# STM32F0x0 register map
File version: 1.2
CPU: CM0 r0p0, little endian, no MPU, no FPU, 3 interrupt priority bits
Registers are 32-bit, read-write, reset 0x0 unless marked. A register's access mark holds for its fields unless they carry their own. Offsets are from the block's base; [hi:lo] are bit positions.

## Flash
Base 0x40022000
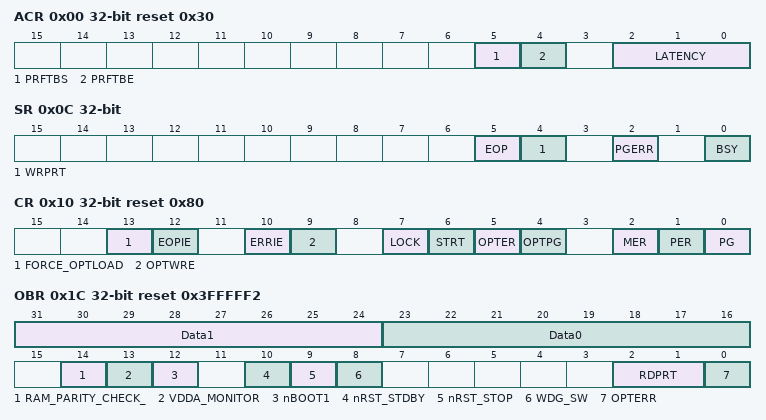
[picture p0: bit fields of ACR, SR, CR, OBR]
0x00 ACR access per field reset 0x30 — Flash access control register
  [5] PRFTBS ro, [4] PRFTBE rw, [2:0] LATENCY rw
0x04 KEYR wo — Flash key register
  [31:0] FKEYR — Flash Key
0x08 OPTKEYR wo — Flash option key register
  [31:0] OPTKEYR — Option byte key
0x0C SR access per field — Flash status register
  [5] EOP rw — End of operation
  [4] WRPRT rw — Write protection error
  [2] PGERR rw — Programming error
  [0] BSY ro — Busy
0x10 CR reset 0x80 — Flash control register
  [13] FORCE_OPTLOAD — Force option byte loading
  [12] EOPIE — End of operation interrupt enable
  [10] ERRIE — Error interrupt enable
  [9] OPTWRE — Option bytes write enable
  [7] LOCK
  [6] STRT — Start
  [5] OPTER — Option byte erase
  [4] OPTPG — Option byte programming
  [2] MER — Mass erase
  [1] PER — Page erase
  [0] PG — Programming
0x14 AR wo — Flash address register
  [31:0] FAR — Flash address
0x1C OBR ro reset 0x3FFFFF2 — Option byte register
  [31:24] Data1
  [23:16] Data0
  [14] RAM_PARITY_CHECK_
  [13] VDDA_MONITOR
  [12] nBOOT1 — BOOT1
  [10] nRST_STDBY
  [9] nRST_STOP
  [8] WDG_SW
  [2:1] RDPRT — Read protection level status
  [0] OPTERR — Option byte error
0x20 WRPR ro reset 0xFFFFFFFF — Write protection register
  [31:0] WRP — Write protect

## DBGMCU — Debug support
Base 0x40015800
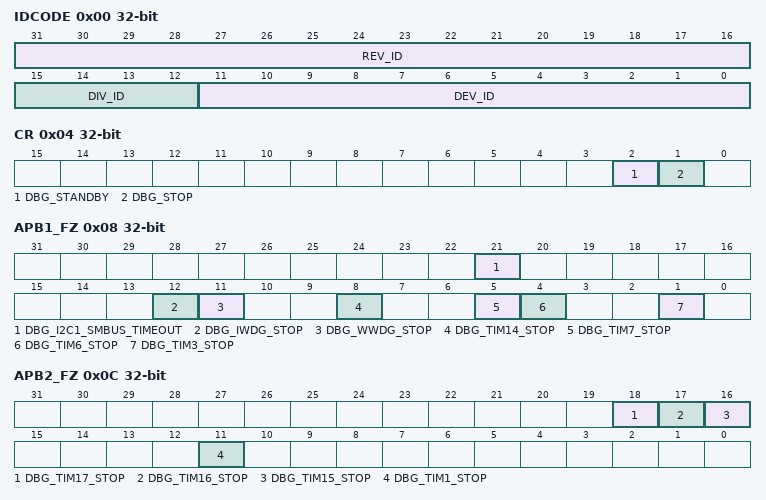
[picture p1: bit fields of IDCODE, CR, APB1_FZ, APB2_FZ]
0x00 IDCODE ro — MCU Device ID Code Register
  [31:16] REV_ID — Revision Identifier
  [15:12] DIV_ID — Division Identifier
  [11:0] DEV_ID — Device Identifier
0x04 CR — Debug MCU Configuration Register
  [2] DBG_STANDBY — Debug Standby Mode
  [1] DBG_STOP — Debug Stop Mode
0x08 APB1_FZ — Debug MCU APB1 freeze register
  [21] DBG_I2C1_SMBUS_TIMEOUT — SMBUS timeout mode stopped when core is halted
  [12] DBG_IWDG_STOP — Debug independent watchdog stopped when core is halted
  [11] DBG_WWDG_STOP — Debug window watchdog stopped when core is halted
  [8] DBG_TIM14_STOP — TIM14 counter stopped when core is halted
  [5] DBG_TIM7_STOP — TIM7 counter stopped when core is halted
  [4] DBG_TIM6_STOP — TIM6 counter stopped when core is halted
  [1] DBG_TIM3_STOP — TIM3 counter stopped when core is halted
0x0C APB2_FZ — Debug MCU APB2 freeze register
  [18] DBG_TIM17_STOP — TIM17 counter stopped when core is halted
  [17] DBG_TIM16_STOP — TIM16 counter stopped when core is halted
  [16] DBG_TIM15_STOP — TIM15 counter stopped when core is halted
  [11] DBG_TIM1_STOP — TIM1 counter stopped when core is halted

## SCB — System control block
Base 0xE000ED00
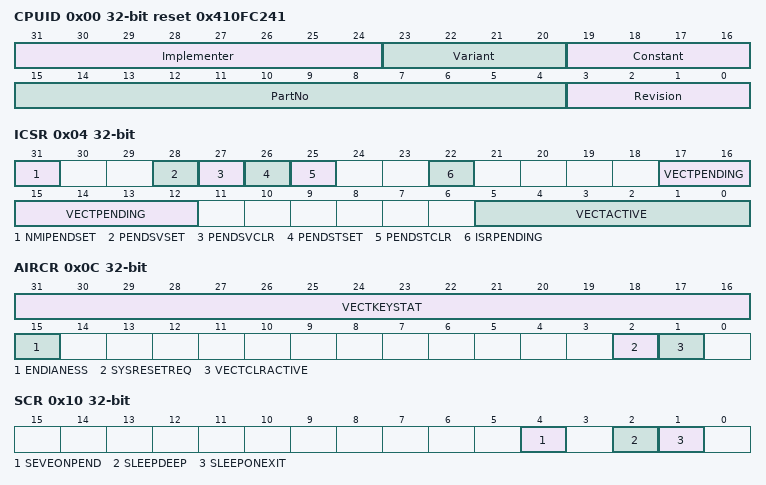
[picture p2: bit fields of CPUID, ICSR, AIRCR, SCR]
0x00 CPUID ro reset 0x410FC241 — CPUID base register
  [31:24] Implementer — Implementer code
  [23:20] Variant — Variant number
  [19:16] Constant — Reads as 0xF
  [15:4] PartNo — Part number of the processor
  [3:0] Revision — Revision number
0x04 ICSR — Interrupt control and state register
  [31] NMIPENDSET — NMI set-pending bit.
  [28] PENDSVSET — PendSV set-pending bit
  [27] PENDSVCLR — PendSV clear-pending bit
  [26] PENDSTSET — SysTick exception set-pending bit
  [25] PENDSTCLR — SysTick exception clear-pending bit
  [22] ISRPENDING — Interrupt pending flag
  [17:12] VECTPENDING — Pending vector
  [5:0] VECTACTIVE — Active vector
0x0C AIRCR — Application interrupt and reset control register
  [31:16] VECTKEYSTAT — Register key
  [15] ENDIANESS
  [2] SYSRESETREQ
  [1] VECTCLRACTIVE
0x10 SCR — System control register
  [4] SEVEONPEND — Send Event on Pending bit
  [2] SLEEPDEEP
  [1] SLEEPONEXIT
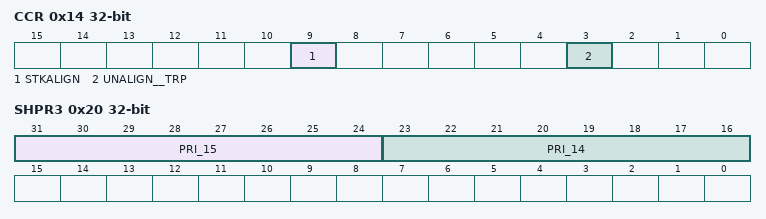
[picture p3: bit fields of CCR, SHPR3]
0x14 CCR — Configuration and control register
  [9] STKALIGN, [3] UNALIGN__TRP
0x1C SHPR2 — System handler priority registers
  [31:24] PRI_11 — Priority of system handler 11
0x20 SHPR3 — System handler priority registers
  [31:24] PRI_15 — Priority of system handler 15
  [23:16] PRI_14 — Priority of system handler 14

## STK — SysTick timer
Base 0xE000E010
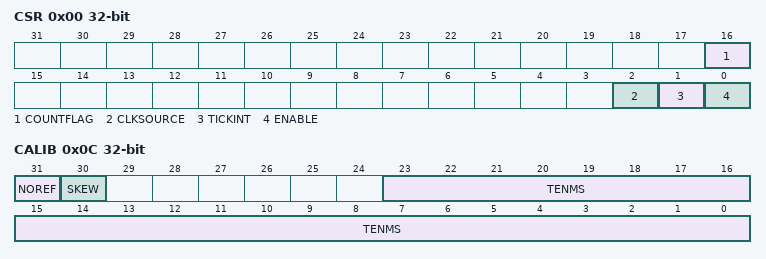
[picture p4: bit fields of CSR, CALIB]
0x00 CSR — SysTick control and status register
  [16] COUNTFLAG
  [2] CLKSOURCE — Clock source selection
  [1] TICKINT — SysTick exception request enable
  [0] ENABLE — Counter enable
0x04 RVR — SysTick reload value register
  [23:0] RELOAD — RELOAD value
0x08 CVR — SysTick current value register
  [23:0] CURRENT — Current counter value
0x0C CALIB — SysTick calibration value register
  [31] NOREF — NOREF flag. Reads as zero
  [30] SKEW — SKEW flag: Indicates whether the TENMS value is exact
  [23:0] TENMS — Calibration value
